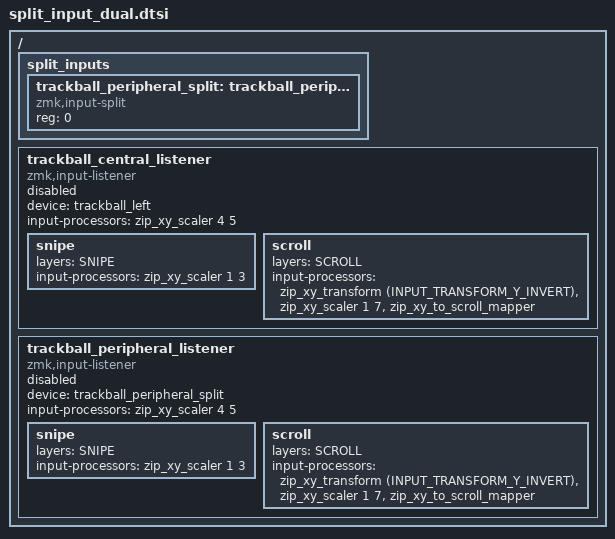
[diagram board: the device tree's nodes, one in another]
#include <dt-bindings/zmk/input_transform.h>
#include <input/processors.dtsi>

#define BASE 0
#define NUMS 1
#define DANGER 2
#define MOUSE 3
#define SCROLL 4
#define SNIPE 5
#define AUTO 6

/ {
  split_inputs {
    #address-cells = <1>;
    #size-cells = <0>;

    trackball_peripheral_split: trackball_peripheral_split@0 {
      compatible = "zmk,input-split";
      reg = <0>;
    };
  };

  trackball_central_listener: trackball_central_listener {
    compatible = "zmk,input-listener";
    status = "disabled";
    device = <&trackball_left>;

    input-processors = <&zip_xy_scaler 4 5>;

    snipe {
      layers = <SNIPE>;
      input-processors = <&zip_xy_scaler 1 3>;
    };

    scroll {
      layers = <SCROLL>;
      input-processors = <&zip_xy_transform (INPUT_TRANSFORM_Y_INVERT)>, <&zip_xy_scaler 1 7>, <&zip_xy_to_scroll_mapper>;
    };
  };

  trackball_peripheral_listener: trackball_peripheral_listener {
    compatible = "zmk,input-listener";
    status = "disabled";
    device = <&trackball_peripheral_split>;

    input-processors = <&zip_xy_scaler 4 5>;

    snipe {
      layers = <SNIPE>;
      input-processors = <&zip_xy_scaler 1 3>;
    };

    scroll {
      layers = <SCROLL>;
      input-processors = <&zip_xy_transform (INPUT_TRANSFORM_Y_INVERT)>, <&zip_xy_scaler 1 7>, <&zip_xy_to_scroll_mapper>;
    };
  };
};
